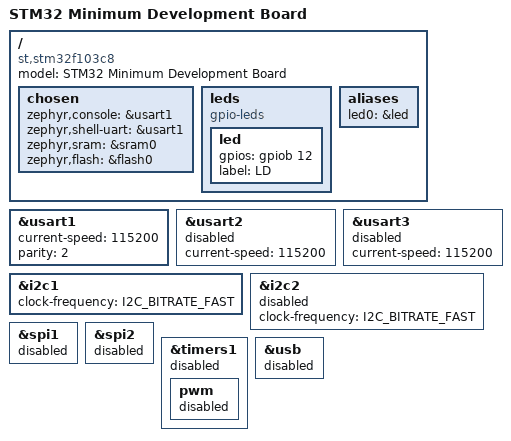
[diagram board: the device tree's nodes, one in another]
/*
 * Copyright (c) 2019, embedjournal.com
 *
 * SPDX-License-Identifier: Apache-2.0
 */

/dts-v1/;
#include <st/f1/stm32f103X8.dtsi>

/ {
	model = "STM32 Minimum Development Board";
	compatible = "st,stm32f103c8";

	chosen {
		zephyr,console = &usart1;
		zephyr,shell-uart = &usart1;
		zephyr,sram = &sram0;
		zephyr,flash = &flash0;
	};

	leds {
		compatible = "gpio-leds";
		led: led {
			gpios = <&gpiob 12 GPIO_INT_ACTIVE_HIGH>;
			label = "LD";
		};
	};

	aliases {
		led0 = &led;
	};
};

&usart1 {
	current-speed = <115200>;
	status = "okay";
	parity = <2>;
};

&usart2 {
	current-speed = <115200>;
	status = "disabled";
};

&usart3 {
	current-speed = <115200>;
	status = "disabled";
};

&i2c1 {
	status = "okay";
	clock-frequency = <I2C_BITRATE_FAST>;
};

&i2c2 {
	status = "disabled";
	clock-frequency = <I2C_BITRATE_FAST>;
};

&spi1 {
	status = "disabled";
};

&spi2 {
	status = "disabled";
};

&timers1 {
	status = "disabled";

	pwm {
		status = "disabled";
	};
};

&usb {
	status = "disabled";
};
